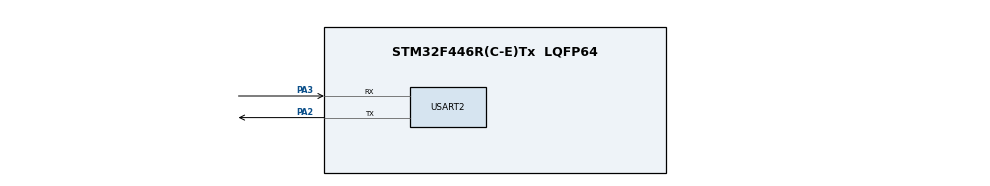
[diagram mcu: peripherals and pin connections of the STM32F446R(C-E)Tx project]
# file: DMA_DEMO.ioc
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Dma.Request0=USART2_TX
Dma.USART2_TX.0.Direction=DMA_MEMORY_TO_PERIPH
Dma.USART2_TX.0.FIFOMode=DMA_FIFOMODE_DISABLE
Dma.USART2_TX.0.Instance=DMA1_Stream6
Dma.USART2_TX.0.MemDataAlignment=DMA_MDATAALIGN_BYTE
Dma.USART2_TX.0.MemInc=DMA_MINC_ENABLE
Dma.USART2_TX.0.Mode=DMA_NORMAL
Dma.USART2_TX.0.PeriphDataAlignment=DMA_PDATAALIGN_BYTE
Dma.USART2_TX.0.PeriphInc=DMA_PINC_DISABLE
Dma.USART2_TX.0.Priority=DMA_PRIORITY_LOW
Mcu.Family=STM32F4
Mcu.Name=STM32F446R(C-E)Tx
Mcu.Package=LQFP64
NVIC.DMA1_Stream6_IRQn=true\:0\:0\:false\:false\:true\:false\:true
NVIC.PriorityGroup=NVIC_PRIORITYGROUP_4
PA2.Mode=Asynchronous
PA2.Signal=USART2_TX
PA3.Mode=Asynchronous
PA3.Signal=USART2_RX
ProjectManager.HeapSize=0x200
ProjectManager.StackSize=0x400
ProjectManager.TargetToolchain=STM32CubeIDE
RCC.CortexFreq_Value=16000000
RCC.USBFreq_Value=96000000
RCC.VCOOutputFreq_Value=192000000
USART2.VirtualMode=VM_ASYNC
board=custom

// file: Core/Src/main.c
/* USER CODE BEGIN Header */
/**
  ******************************************************************************
  * @file           : main.c
  * @brief          : Main program body
  ******************************************************************************
  * @attention
  *
  * <h2><center>&copy; Copyright (c) 2021 STMicroelectronics.
  * All rights reserved.</center></h2>
  *
  * This software component is licensed by ST under BSD 3-Clause license,
  * the "License"; You may not use this file except in compliance with the
  * License. You may obtain a copy of the License at:
  *                        opensource.org/licenses/BSD-3-Clause
  *
  ******************************************************************************
  */
/* USER CODE END Header */
#include "main.h"

UART_HandleTypeDef huart2;
DMA_HandleTypeDef hdma_usart2_tx;

void SystemClock_Config(void);
static void MX_GPIO_Init(void);
static void MX_DMA_Init(void);
static void MX_USART2_UART_Init(void);

int main(void)
{

  /* MCU Configuration--------------------------------------------------------*/

  /* Reset of all peripherals, Initializes the Flash interface and the Systick. */
  HAL_Init();

  /* Configure the system clock */
  SystemClock_Config();

  /* USER CODE BEGIN SysInit */
  HAL_NVIC_SetPriority(USART2_IRQn, 0, 0);
  HAL_NVIC_EnableIRQ(USART2_IRQn);
  /* USER CODE END SysInit */

  /* Initialize all configured peripherals */
  MX_GPIO_Init();
  MX_DMA_Init();
  MX_USART2_UART_Init();
  /* USER CODE BEGIN 2 */
  uint8_t tx_buff[] = "Hello from STM32 \n";
  uint8_t rx_buff[10];
  /* USER CODE END 2 */

  /* Infinite loop */
  while (1)
  {

    /* USER CODE BEGIN 3 */
	HAL_UART_Transmit_DMA(&huart2, tx_buff, strlen(tx_buff));

	HAL_Delay(1000);
  }
  /* USER CODE END 3 */
}

void SystemClock_Config(void)
{
  RCC_OscInitTypeDef RCC_OscInitStruct = {0};
  RCC_ClkInitTypeDef RCC_ClkInitStruct = {0};

  /** Configure the main internal regulator output voltage
  */
  __HAL_RCC_PWR_CLK_ENABLE();
  __HAL_PWR_VOLTAGESCALING_CONFIG(PWR_REGULATOR_VOLTAGE_SCALE3);
  /** Initializes the RCC Oscillators according to the specified parameters
  * in the RCC_OscInitTypeDef structure.
  */
  RCC_OscInitStruct.OscillatorType = RCC_OSCILLATORTYPE_HSI;
  RCC_OscInitStruct.HSIState = RCC_HSI_ON;
  RCC_OscInitStruct.HSICalibrationValue = RCC_HSICALIBRATION_DEFAULT;
  RCC_OscInitStruct.PLL.PLLState = RCC_PLL_NONE;
  if (HAL_RCC_OscConfig(&RCC_OscInitStruct) != HAL_OK)
  {
    Error_Handler();
  }
  /** Initializes the CPU, AHB and APB buses clocks
  */
  RCC_ClkInitStruct.ClockType = RCC_CLOCKTYPE_HCLK|RCC_CLOCKTYPE_SYSCLK
                              |RCC_CLOCKTYPE_PCLK1|RCC_CLOCKTYPE_PCLK2;
  RCC_ClkInitStruct.SYSCLKSource = RCC_SYSCLKSOURCE_HSI;
  RCC_ClkInitStruct.AHBCLKDivider = RCC_SYSCLK_DIV1;
  RCC_ClkInitStruct.APB1CLKDivider = RCC_HCLK_DIV1;
  RCC_ClkInitStruct.APB2CLKDivider = RCC_HCLK_DIV1;

  if (HAL_RCC_ClockConfig(&RCC_ClkInitStruct, FLASH_LATENCY_0) != HAL_OK)
  {
    Error_Handler();
  }
}

static void MX_USART2_UART_Init(void)
{

  huart2.Instance = USART2;
  huart2.Init.BaudRate = 115200;
  huart2.Init.WordLength = UART_WORDLENGTH_8B;
  huart2.Init.StopBits = UART_STOPBITS_1;
  huart2.Init.Parity = UART_PARITY_NONE;
  huart2.Init.Mode = UART_MODE_TX_RX;
  huart2.Init.HwFlowCtl = UART_HWCONTROL_NONE;
  huart2.Init.OverSampling = UART_OVERSAMPLING_16;
  if (HAL_UART_Init(&huart2) != HAL_OK)
  {
    Error_Handler();
  }

}

static void MX_DMA_Init(void)
{

  /* DMA controller clock enable */
  __HAL_RCC_DMA1_CLK_ENABLE();

  /* DMA interrupt init */
  /* DMA1_Stream6_IRQn interrupt configuration */
  HAL_NVIC_SetPriority(DMA1_Stream6_IRQn, 0, 0);
  HAL_NVIC_EnableIRQ(DMA1_Stream6_IRQn);

}

static void MX_GPIO_Init(void)
{

  /* GPIO Ports Clock Enable */
  __HAL_RCC_GPIOA_CLK_ENABLE();

}

/* USER CODE BEGIN 4 */

void HAL_UART_RxCpltCallback(UART_HandleTypeDef *huart)
{
	while(1);
}

void HAL_UART_TxCpltCallback(UART_HandleTypeDef *huart)
{
	__NOP();
}

/* USER CODE END 4 */

void Error_Handler(void)
{
}

/************************ (C) COPYRIGHT STMicroelectronics *****END OF FILE****/
